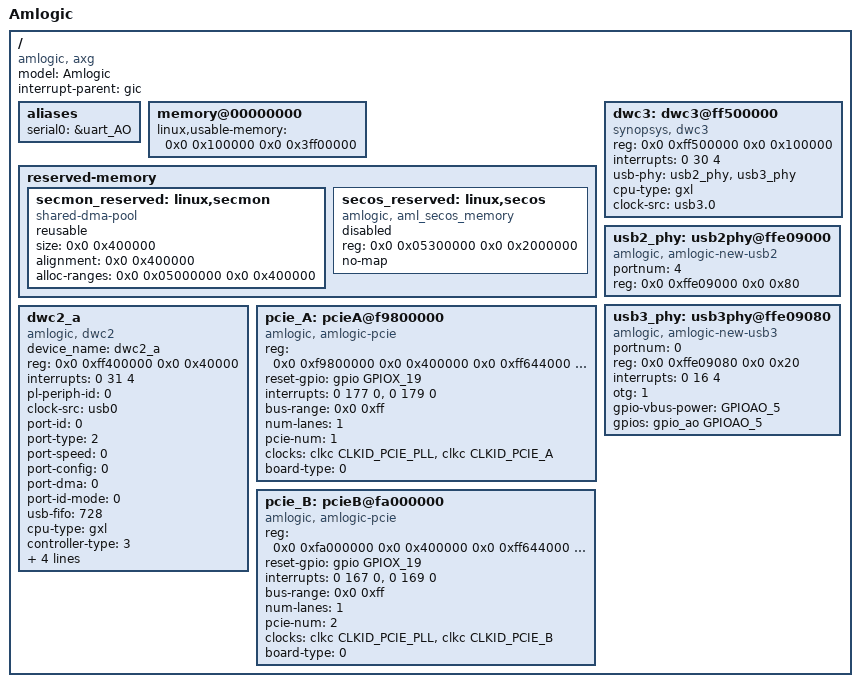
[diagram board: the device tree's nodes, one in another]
/*
 * arch/arm64/boot/dts/amlogic/axg_a113d_skt.dts
 *
 * Copyright (C) 2017 Amlogic, Inc. All rights reserved.
 *
 * This program is free software; you can redistribute it and/or modify
 * it under the terms of the GNU General Public License as published by
 * the Free Software Foundation; either version 2 of the License, or
 * (at your option) any later version.
 *
 * This program is distributed in the hope that it will be useful, but WITHOUT
 * ANY WARRANTY; without even the implied warranty of MERCHANTABILITY or
 * FITNESS FOR A PARTICULAR PURPOSE.  See the GNU General Public License for
 * more details.
 *
 */

/dts-v1/;

#include "mesonaxg.dtsi"

/ {
	model = "Amlogic";
	compatible = "amlogic, axg";
	interrupt-parent = <&gic>;
	#address-cells = <2>;
	#size-cells = <2>;

	aliases {
		serial0 = &uart_AO;
	};

	memory@00000000 {
		device_type = "memory";
		linux,usable-memory = <0x0 0x100000 0x0 0x3ff00000>;
	};

	reserved-memory {
		#address-cells = <2>;
		#size-cells = <2>;
		ranges;
		/* global autoconfigured region for contiguous allocations */
		secmon_reserved:linux,secmon {
			compatible = "shared-dma-pool";
			reusable;
			size = <0x0 0x400000>;
			alignment = <0x0 0x400000>;
			alloc-ranges = <0x0 0x05000000 0x0 0x400000>;
		};

		secos_reserved:linux,secos {
			status = "disable";
			compatible = "amlogic, aml_secos_memory";
			reg = <0x0 0x05300000 0x0 0x2000000>;
			no-map;
		};
	};



	dwc3: dwc3@ff500000 {
		compatible = "synopsys, dwc3";
		status = "okay";
		reg = <0x0 0xff500000 0x0 0x100000>;
		interrupts = <0 30 4>;
		usb-phy = <&usb2_phy>, <&usb3_phy>;
		cpu-type = "gxl";
		clock-src = "usb3.0";
	};

	usb2_phy: usb2phy@ffe09000 {
		compatible = "amlogic, amlogic-new-usb2";
		status = "okay";
		portnum = <4>;
		reg = <0x0 0xffe09000 0x0 0x80>;
	};
	usb3_phy: usb3phy@ffe09080 {
		compatible = "amlogic, amlogic-new-usb3";
		status = "okay";
		portnum = <0>;
		reg = <0x0 0xffe09080 0x0 0x20>;
		interrupts = <0 16 4>;
		otg = <1>;
		gpio-vbus-power = "GPIOAO_5";
		gpios = <&gpio_ao GPIOAO_5 GPIO_ACTIVE_HIGH>;
	};

	dwc2_a {
		compatible = "amlogic, dwc2";
		device_name = "dwc2_a";
		reg = <0x0 0xff400000 0x0 0x40000>;
		status = "okay";
		interrupts = <0 31 4>;
		pl-periph-id = <0>; /** lm name */
		clock-src = "usb0"; /** clock src */
		port-id = <0>;  /** ref to mach/usb.h */
		port-type = <2>;        /** 0: otg, 1: host, 2: slave */
		port-speed = <0>; /** 0: default, high, 1: full */
		port-config = <0>; /** 0: default */
		/*0:default,1:single,2:incr,3:incr4,4:incr8,5:incr16,6:disable*/
		port-dma = <0>;
		port-id-mode = <0>; /** 0: hardware, 1: sw_host, 2: sw_slave*/
		usb-fifo = <728>;
		cpu-type = "gxl";
		/** 0: normal, 1: otg+dwc3 host only, 2: otg+dwc3 device only*/
		controller-type = <3>;
		phy-reg = <0xffe09000>;
		phy-reg-size = <0xa0>;
		clocks = <&clkc CLKID_USB_GENERAL
			&clkc CLKID_USB1_TO_DDR
			&clkc CLKID_USB1>;
		clock-names = "usb_general",
			"usb1",
			"usb1_to_ddr";
	};

	pcie_A: pcieA@f9800000 {
		compatible = "amlogic, amlogic-pcie", "snps,dw-pcie";
		reg = <0x0 0xf9800000 0x0 0x400000
				0x0 0xff644000 0x0 0x2000
				0x0 0xff646000 0x0 0x2000
				0x0 0xffd01080 0x0 0x10
				0x0 0xf9c00000 0x0 0x100000>;
		reg-names = "elbi", "phy", "cfg", "reset", "config";
		reset-gpio = <&gpio GPIOX_19 GPIO_ACTIVE_HIGH>;
		interrupts = <0 177 0>, <0 179 0>;
		#interrupt-cells = <1>;
		bus-range = <0x0 0xff>;
		#address-cells = <3>;
		#size-cells = <2>;
		device_type = "pci";
		ranges = <0x81000000 0 0	  0 0xf9d00000  0x0 0x10000
			/*downstream I/O */
			  0x82000000 0 0xf9d10000 0x0 0xf9d10000 0 0x002f0000>;
			/* non-prefetchable memory */
		num-lanes = <1>;
		pcie-num = <1>;

		clocks = <&clkc CLKID_PCIE_PLL
		&clkc CLKID_PCIE_A>;
		clock-names = "pcie_refpll",
				"pcie_a";
		board-type = <0>;/*0:skt 1:s400*/
		status = "okay";
	};

	pcie_B: pcieB@fa000000 {
		compatible = "amlogic, amlogic-pcie", "snps,dw-pcie";
		reg = <0x0 0xfa000000 0x0 0x400000
				0x0 0xff644000 0x0 0x2000
				0x0 0xff648000 0x0 0x2000
				0x0 0xffd01080 0x0 0x10
				0x0 0xfa400000 0x0 0x100000>;
		reg-names = "elbi", "phy", "cfg", "reset", "config";
		reset-gpio = <&gpio GPIOX_19 GPIO_ACTIVE_HIGH>;
		interrupts = <0 167 0>, <0 169 0>;
		#interrupt-cells = <1>;
		bus-range = <0x0 0xff>;
		#address-cells = <3>;
		#size-cells = <2>;
		device_type = "pci";
		ranges = <0x81000000 0 0	  0  0xfa500000 0x0 0x10000
			/* downstream I/O */
			0x82000000 0 0xfa510000 0x0 0xfa510000 0 0x002f0000>;
			/* non-prefetchable memory */
		num-lanes = <1>;
		pcie-num = <2>;

		clocks = <&clkc CLKID_PCIE_PLL
			&clkc CLKID_PCIE_B>;
		clock-names = "pcie_refpll",
			"pcie_b";
		board-type = <0>;/*0:skt 1:s400*/
		status = "okay";
	};

}; /* end of / */


